# LPC18xx register map
File version: 0.23
CPU: CM3 r0p0, little endian, no MPU, no FPU, 3 interrupt priority bits
Registers are 32-bit, read-write, reset 0x0 unless marked. A register's access mark holds for its fields unless they carry their own. Offsets are from the block's base; [hi:lo] are bit positions; 'fields as' and 'values as' point back to an identical list.

## SPIFI — SPI Flash Interface (SPIFI)
Base 0x40003000
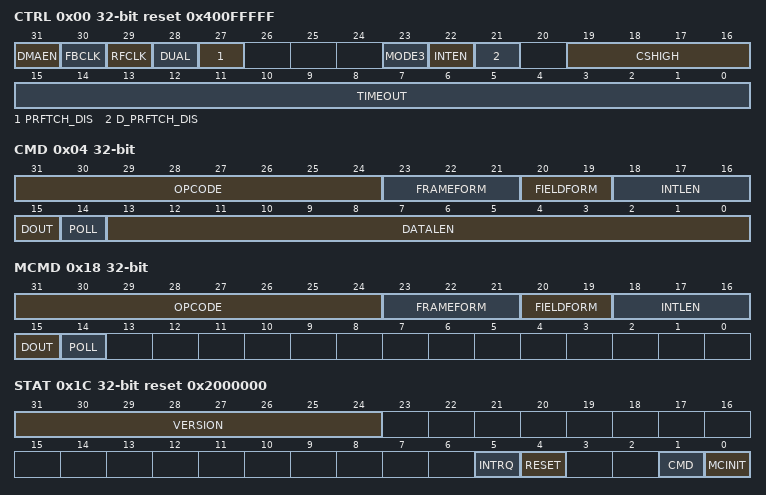
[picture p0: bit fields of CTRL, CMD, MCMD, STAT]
0x00 CTRL reset 0x400FFFFF — SPIFI control register
  [31] DMAEN — A 1 in this bit enables the DMA Request output from the SPIFI. Set this bit only when a DMA channel is used to transfer data in peripheral mode. Do not set this bit when a DMA channel is used for memory-to-memory transfers from the SPIFI memory area. DRQEN should only be used in Command mode.
  [30] FBCLK — Feedback clock select.
    0=INTERNAL_CLOCK (Internal clock. The SPIFI samples read data using an internal clock.); 1=FEEDBACK_CLOCK (Feedback clock. Read data is sampled using a feedback clock from the SCK pin. This allows slightly more time for each received bit. MODE3, RFCLK, and FBCLK should not all be 1, because in this case there is no final rising edge on SCK on which to sample the last data bit of the frame.)
  [29] RFCLK — Select active clock edge for input data.
    0=RISING_EDGE (Rising edge. Read data is sampled on rising edges on the clock, as in classic SPI operation.); 1=FALLING_EDGE (Falling edge. Read data is sampled on falling edges of the clock, allowing a full serial clock of of time in order to maximize the serial clock frequency. MODE3, RFCLK, and FBCLK should not all be 1, because in this case there is no final rising edge on SCK on which to sample the last data bit of the frame.)
  [28] DUAL — Select dual protocol.
    0=QUAD_PROTOCOL (Quad protocol. This protocol uses IO3:0.); 1=DUAL_PROTOCOL (Dual protocol. This protocol uses IO1:0.)
  [27] PRFTCH_DIS — Cache prefetching enable. The SPIFI includes an internal cache. A 1 in this bit disables prefetching of cache lines.
    0=ENABLE (Enable. Cache prefetching enabled.); 1=DISABLE (Disable. Disables prefetching of cache lines.)
  [23] MODE3 — SPI Mode 3 select.
    0=SCK_LOW (SCK LOW. The SPIFI drives SCK low after the rising edge at which the last bit of each command is captured, and keeps it low while CS is HIGH.); 1=SCK_HIGH (SCK HIGH. the SPIFI keeps SCK high after the rising edge for the last bit of each command and while CS is HIGH, and drives it low after it drives CS LOW. (Known serial flash devices can handle either mode, but some devices may require a particular mode for proper operation.) MODE3, RFCLK, and FBCLK should not all be 1, because in this case there is no final rising edge on SCK on which to sample the last data bit of the frame.)
  [22] INTEN — If this bit is 1 when a command ends, the SPIFI will assert its interrupt request output. See INTRQ in the status register for further details.
  [21] D_PRFTCH_DIS — This bit allows conditioning of memory mode prefetches based on the AHB HPROT (instruction/data) access information. A 1 in this register means that the SPIFI will not attempt a speculative prefetch when it encounters data accesses.
  [19:16] CSHIGH — This field controls the minimum CS high time, expressed as a number of serial clock periods minus one.
  [15:0] TIMEOUT — This field contains the number of serial clock periods without the processor reading data in memory mode, which will cause the SPIFI hardware to terminate the command by driving the CS pin high and negating the CMD bit in the Status register. (This allows the flash memory to enter a lower-power state.) If the processor reads data from the flash region after a time-out, the command in the Memory Command Register is issued again.
0x04 CMD — SPIFI command register
  [31:24] OPCODE — The opcode of the command (not used for some FRAMEFORM values).
  [23:21] FRAMEFORM — This field controls the opcode and address fields.
    1=OPCODE (Opcode. Opcode only, no address.); 2=OPCODE_ONE_BYTE (Opcode one byte. Opcode, least significant byte of address.); 3=OPCODE_TWO_BYTES (Opcode two bytes. Opcode, two least significant bytes of address.); 4=OPCODE_THREE_BYTES (Opcode three bytes. Opcode, three least significant bytes of address.); 5=OPCODE_FOUR_BYTES (Opcode four bytes. Opcode, 4 bytes of address.); 6=NO_OPCODE_THREE_BYTE (No opcode three bytes. No opcode, 3 least significant bytes of address.); 7=NO_OPCODE_FOUR_BYTES (No opcode four bytes. No opcode, 4 bytes of address.)
  [20:19] FIELDFORM — This field controls how the fields of the command are sent.
    0=ALL_SERIAL (All serial. All fields of the command are serial.); 1=QUADDUAL_DATA (Quad/dual data. Data field is quad/dual, other fields are serial.); 2=SERIAL_OPCODE (Serial opcode. Opcode field is serial. Other fields are quad/dual.); 3=ALL_QUADDUAL (All quad/dual. All fields of the command are in quad/dual format.)
  [18:16] INTLEN — This field controls how many intermediate bytes precede the data. (Each such byte may require 8 or 2 SCK cycles, depending on whether the intermediate field is in serial, 2-bit, or 4-bit format.) Intermediate bytes are output by the SPIFI, and include post-address control information, dummy and delay bytes. See the description of the Intermediate Data register for the contents of such bytes.
  [15] DOUT — If the DATALEN field is not zero, this bit controls the direction of the data:
    0=INPUT_FROM_SERIAL_FL (Input from serial flash.); 1=OUTPUT_TO_SERIAL_FLA (Output to serial flash.)
  [14] POLL — This bit should be written as 1 only with an opcode that a) contains an input data field, and b) causes the serial flash device to return byte status repetitively (e.g., a Read Status command). When this bit is 1, the SPIFI hardware continues to read bytes until the test specified by the dataLen field is met. The hardware tests the bit in each status byte selected by DATALEN bits 2:0, until a bit is found that is equal to DATALEN bit 3. When the test succeeds, the SPIFI captures the byte that meets this test so that it can be read from the Data Register, and terminates the command by raising CS. The end-of-command interrupt can be enabled to inform software when this occurs
  [13:0] DATALEN — Except when the POLL bit in this register is 1, this field controls how many data bytes are in the command. 0 indicates that the command does not contain a data field.
0x08 ADDR — SPIFI address register
  [31:0] ADDRESS
0x0C IDATA — SPIFI intermediate data register
  [31:0] IDATA — Value of intermediate bytes.
0x10 CLIMIT reset 0x8000000 — SPIFI cache limit register
  [31:0] CLIMIT — Zero-based upper limit of cacheable memory
0x14 DATA — SPIFI data register
  [31:0] DATA — Input or output data
0x18 MCMD — SPIFI memory command register
  [31:24] OPCODE — The opcode of the command (not used for some FRAMEFORM values).
  [23:21] FRAMEFORM — This field controls the opcode and address fields.
    2=OPCODE_ONE_BYTE (Opcode one byte. Opcode, least-significant byte of address.); 3=OPCODE_TWO_BYTES (Opcode two bytes. Opcode, 2 least-significant bytes of address.); 4=OPCODE_THREE_BYTES (Opcode three bytes. Opcode, 3 least-significant bytes of address.); 5=OPCODE_FOUR_BYTES (Opcode four bytes. Opcode, 4 bytes of address.); 6=NO_OPCODE_THREE_BYTE (No opcode three bytes. No opcode, 3 least-significant bytes of address.); 7=NO_OPCODE_FOUR_BYTES (No opcode, 4 bytes of address.)
  [20:19] FIELDFORM — This field controls how the fields of the command are sent.
    values as CMD.FIELDFORM
  [18:16] INTLEN — This field controls how many intermediate bytes precede the data. (Each such byte may require 8 or 2 SCK cycles, depending on whether the intermediate field is in serial, 2-bit, or 4-bit format.) Intermediate bytes are output by the SPIFI, and include post-address control information, dummy and delay bytes. See the description of the Intermediate Data register for the contents of such bytes.
  [15] DOUT — This bit should be written as 0.
  [14] POLL — This bit should be written as 0.
0x1C STAT reset 0x2000000 — SPIFI status register
  [31:24] VERSION — The SPIFI hardware described in this chapter returns
  [5] INTRQ — This bit reflects the SPIFI interrupt request. Write a 1 to this bit to clear it. This bit is set when a CMD was previously 1 and has been cleared due to the deassertion of CS.
  [4] RESET — Write a 1 to this bit to abort a current command or memory mode. This bit is cleared when the hardware is ready for a new command to be written to the Command register.
  [1] CMD — This bit is 1 when the Command register is written. It is cleared by a hardware reset, a write to the RESET bit in this register, or the deassertion of CS which indicates that the command has completed communication with the SPI Flash.
  [0] MCINIT — This bit is set when software successfully writes the Memory Command register, and is cleared by Reset or by writing a 1 to the RESET bit in this register.
